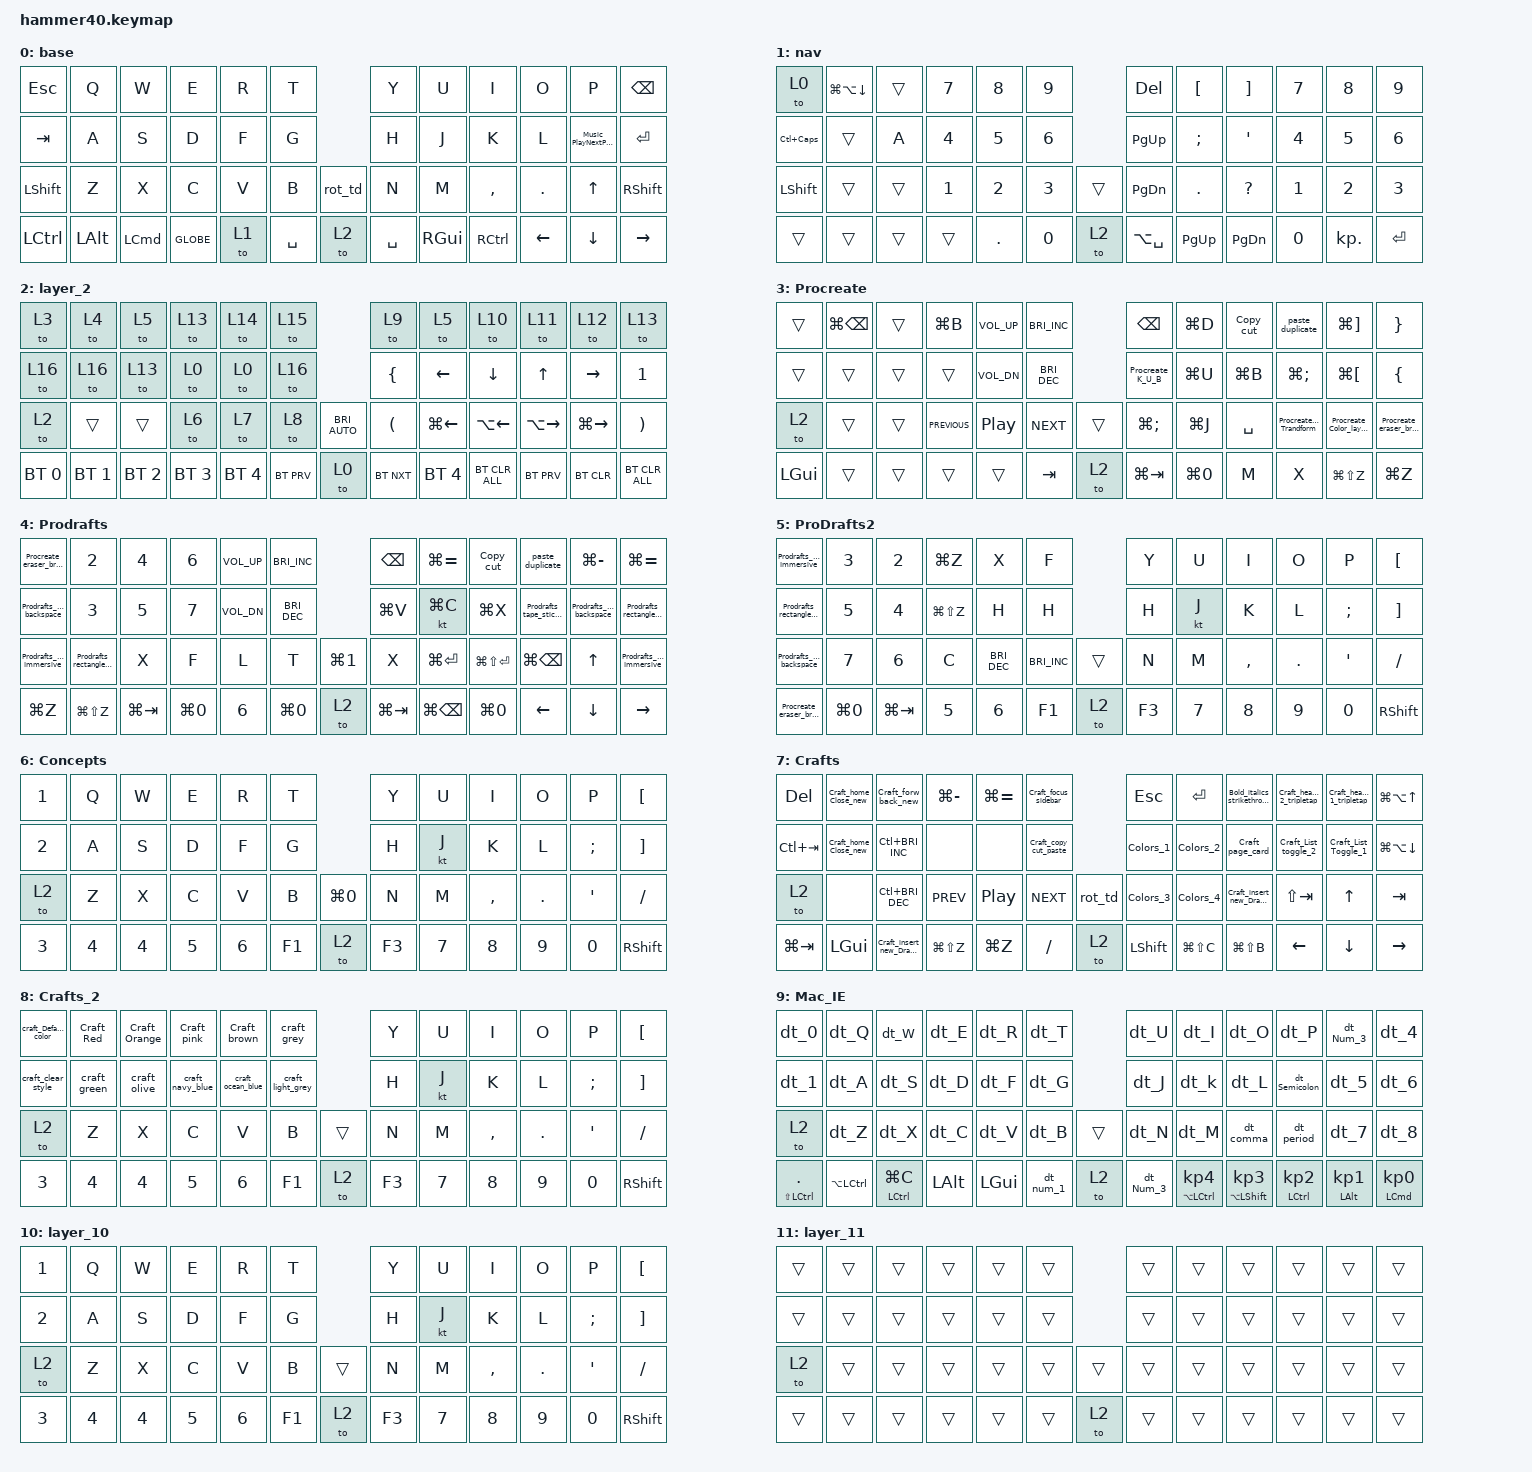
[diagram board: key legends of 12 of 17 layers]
/*
 * Copyright (c) 2020 The ZMK Contributors
 *
 * SPDX-License-Identifier: MIT
 */

#include <behaviors.dtsi>
#include <dt-bindings/zmk/bt.h>
#include <dt-bindings/zmk/keys.h>

/* Layers */

#define BASE 0
#define LOWR 1
#define NAV 2

/ {
    combos {
        compatible = "zmk,combos";

        combo_capsw {
            timeout-ms = <50>;
            key-positions = <16 19>;
            bindings = <&caps_word>;
        };

        combo_bootl {
            timeout-ms = <50>;
            key-positions = <0 1 2>;
            bindings = <&bootloader>;
        };

        combo_reset {
            timeout-ms = <50>;
            key-positions = <10 11 12>;
            bindings = <&sys_reset>;
        };
    };

    behaviors {
        rot_td: rot_tap_dance {
            compatible = "zmk,behavior-tap-dance";
            #binding-cells = <0>;
            tapping-term-ms = <250>;
            bindings = <&kp C_PP>, <&kp C_NEXT>, <&kp C_PREV>;
        };

        ble_encoder: ble_encoder {
            compatible = "zmk,behavior-sensor-rotate";
            #sensor-binding-cells = <0>;
            bindings = <&bt BT_NXT>, <&bt BT_PRV>;
        };

        dt_1: dt_1 {
            compatible = "zmk,behavior-tap-dance";
            label = "DT_1";
            #binding-cells = <0>;
            tapping-term-ms = <250>;
            bindings = <&kp N1>, <&kp RS(NUMBER_1)>, <&kp RA(NUMBER_1)>;
        };

        dt_2: dt_2 {
            compatible = "zmk,behavior-tap-dance";
            label = "DT_2";
            #binding-cells = <0>;
            tapping-term-ms = <250>;
            bindings = <&kp NUMBER_2>, <&kp RS(NUMBER_2)>, <&kp RA(NUMBER_2)>;
        };

        dt_3: dt_3 {
            compatible = "zmk,behavior-tap-dance";
            label = "DT_3";
            #binding-cells = <0>;
            tapping-term-ms = <250>;
            bindings = <&kp NUMBER_3>, <&kp RS(NUMBER_3)>, <&kp RA(NUMBER_3)>;
        };

        dt_0: dt_0 {
            compatible = "zmk,behavior-tap-dance";
            label = "DT_0";
            #binding-cells = <0>;
            tapping-term-ms = <250>;
            bindings = <&kp N0>, <&kp RS(N0)>, <&kp RA(N0)>;
        };

        dt_4: dt_4 {
            compatible = "zmk,behavior-tap-dance";
            label = "DT_4";
            #binding-cells = <0>;
            tapping-term-ms = <250>;
            bindings = <&kp NUMBER_4>, <&kp RS(NUMBER_4)>, <&kp RA(NUMBER_4)>;
        };

        dt_5: dt_5 {
            compatible = "zmk,behavior-tap-dance";
            label = "DT_5";
            #binding-cells = <0>;
            tapping-term-ms = <250>;
            bindings = <&kp N5>, <&kp RS(N5)>, <&kp RA(N5)>;
        };

        dt_6: dt_6 {
            compatible = "zmk,behavior-tap-dance";
            label = "DT_6";
            #binding-cells = <0>;
            tapping-term-ms = <250>;
            bindings = <&kp N6>, <&kp RS(N6)>, <&kp RA(N6)>;
        };

        dt_7: dt_7 {
            compatible = "zmk,behavior-tap-dance";
            label = "DT_7";
            #binding-cells = <0>;
            tapping-term-ms = <250>;
            bindings = <&kp N7>, <&kp RS(N7)>, <&kp RA(N7)>;
        };

        dt_8: dt_8 {
            compatible = "zmk,behavior-tap-dance";
            label = "DT_8";
            #binding-cells = <0>;
            tapping-term-ms = <250>;
            bindings = <&kp N8>, <&kp RS(N8)>, <&kp RA(N8)>;
        };

        dt_9: dt_9 {
            compatible = "zmk,behavior-tap-dance";
            label = "DT_9";
            #binding-cells = <0>;
            tapping-term-ms = <250>;
            bindings = <&kp N9>, <&kp RS(N9)>, <&kp RA(N9)>;
        };

        dt_Q: dt_Q {
            compatible = "zmk,behavior-tap-dance";
            label = "DT_Q";
            #binding-cells = <0>;
            tapping-term-ms = <250>;
            bindings = <&kp Q>, <&kp RS(Q)>, <&kp RA(Q)>;
        };

        dt_W: dt_W {
            compatible = "zmk,behavior-tap-dance";
            label = "DT_W";
            #binding-cells = <0>;
            tapping-term-ms = <250>;
            bindings = <&kp W>, <&kp RS(W)>, <&kp RA(W)>;
        };

        dt_E: dt_E {
            compatible = "zmk,behavior-tap-dance";
            label = "DT_E";
            #binding-cells = <0>;
            tapping-term-ms = <250>;
            bindings = <&kp E>, <&kp RS(E)>, <&kp RA(E)>;
        };

        dt_R: dt_R {
            compatible = "zmk,behavior-tap-dance";
            label = "DT_R";
            #binding-cells = <0>;
            tapping-term-ms = <250>;
            bindings = <&kp R>, <&kp RS(R)>, <&kp RA(R)>;
        };

        dt_T: dt_T {
            compatible = "zmk,behavior-tap-dance";
            label = "DT_T";
            #binding-cells = <0>;
            tapping-term-ms = <250>;
            bindings = <&kp T>, <&kp RS(T)>, <&kp RA(T)>;
        };

        dt_A: dt_A {
            compatible = "zmk,behavior-tap-dance";
            label = "DT_A";
            #binding-cells = <0>;
            tapping-term-ms = <250>;
            bindings = <&kp A>, <&kp RS(A)>, <&kp RA(A)>;
        };

        dt_S: dt_S {
            compatible = "zmk,behavior-tap-dance";
            label = "DT_S";
            #binding-cells = <0>;
            tapping-term-ms = <250>;
            bindings = <&kp S>, <&kp RS(S)>, <&kp RA(S)>;
        };

        dt_D: dt_D {
            compatible = "zmk,behavior-tap-dance";
            label = "DT_D";
            #binding-cells = <0>;
            tapping-term-ms = <250>;
            bindings = <&kp D>, <&kp RS(D)>, <&kp RA(D)>;
        };

        dt_F: dt_F {
            compatible = "zmk,behavior-tap-dance";
            label = "DT_F";
            #binding-cells = <0>;
            tapping-term-ms = <250>;
            bindings = <&kp F>, <&kp RS(F)>, <&kp RA(F)>;
        };

        dt_G: dt_G {
            compatible = "zmk,behavior-tap-dance";
            label = "DT_G";
            #binding-cells = <0>;
            tapping-term-ms = <250>;
            bindings = <&kp G>, <&kp RS(G)>, <&kp RA(G)>;
        };

        dt_Z: dt_Z {
            compatible = "zmk,behavior-tap-dance";
            label = "DT_Z";
            #binding-cells = <0>;
            tapping-term-ms = <250>;
            bindings = <&kp Z>, <&kp RS(Z)>, <&kp RA(Z)>;
        };

        dt_X: dt_X {
            compatible = "zmk,behavior-tap-dance";
            label = "DT_X";
            #binding-cells = <0>;
            tapping-term-ms = <250>;
            bindings = <&kp X>, <&kp RS(X)>, <&kp RA(X)>;
        };

        dt_C: dt_C {
            compatible = "zmk,behavior-tap-dance";
            label = "DT_C";
            #binding-cells = <0>;
            tapping-term-ms = <250>;
            bindings = <&kp C>, <&kp RS(C)>, <&kp RA(C)>;
        };

        dt_V: dt_V {
            compatible = "zmk,behavior-tap-dance";
            label = "DT_V";
            #binding-cells = <0>;
            tapping-term-ms = <250>;
            bindings = <&kp V>, <&kp RS(V)>, <&kp RA(V)>;
        };

        dt_B: dt_B {
            compatible = "zmk,behavior-tap-dance";
            label = "DT_B";
            #binding-cells = <0>;
            tapping-term-ms = <250>;
            bindings = <&kp B>, <&kp RS(B)>, <&kp RA(B)>;
        };

        dt_U: dt_U {
            compatible = "zmk,behavior-tap-dance";
            label = "DT_U";
            #binding-cells = <0>;
            tapping-term-ms = <250>;
            bindings = <&kp U>, <&kp RS(U)>, <&kp RA(U)>;
        };

        dt_I: dt_I {
            compatible = "zmk,behavior-tap-dance";
            label = "DT_I";
            #binding-cells = <0>;
            tapping-term-ms = <250>;
            bindings = <&kp I>, <&kp RS(I)>, <&kp RA(I)>;
        };

        dt_O: dt_O {
            compatible = "zmk,behavior-tap-dance";
            label = "DT_O";
            #binding-cells = <0>;
            tapping-term-ms = <250>;
            bindings = <&kp O>, <&kp RS(O)>, <&kp RA(O)>;
        };

        dt_J: dt_J {
            compatible = "zmk,behavior-tap-dance";
            label = "DT_J";
            #binding-cells = <0>;
            tapping-term-ms = <250>;
            bindings = <&kp J>, <&kp RS(J)>, <&kp RA(J)>;
        };

        dt_k: dt_k {
            compatible = "zmk,behavior-tap-dance";
            label = "DT_K";
            #binding-cells = <0>;
            tapping-term-ms = <250>;
            bindings = <&kp K>, <&kp RS(K)>, <&kp RA(K)>;
        };

        dt_L: dt_L {
            compatible = "zmk,behavior-tap-dance";
            label = "DT_L";
            #binding-cells = <0>;
            tapping-term-ms = <250>;
            bindings = <&kp L>, <&kp RS(L)>, <&kp RA(L)>;
        };

        dt_M: dt_M {
            compatible = "zmk,behavior-tap-dance";
            label = "DT_M";
            #binding-cells = <0>;
            tapping-term-ms = <250>;
            bindings = <&kp M>, <&kp RS(M)>, <&kp RA(M)>;
        };

        dt_N: dt_N {
            compatible = "zmk,behavior-tap-dance";
            label = "DT_N";
            #binding-cells = <0>;
            tapping-term-ms = <250>;
            bindings = <&kp N>, <&kp RS(N)>, <&kp RA(N)>;
        };

        dt_P: dt_P {
            compatible = "zmk,behavior-tap-dance";
            label = "DT_P";
            #binding-cells = <0>;
            tapping-term-ms = <250>;
            bindings = <&kp P>, <&kp RS(P)>, <&kp RA(P)>;
        };

        dt_Semicolon: dt_Semicolon {
            compatible = "zmk,behavior-tap-dance";
            label = "DT_SEMICOLON";
            #binding-cells = <0>;
            tapping-term-ms = <250>;
            bindings = <&kp SEMI>, <&kp RS(SEMI)>, <&kp RA(SEMI)>;
        };

        dt_comma: dt_comma {
            compatible = "zmk,behavior-tap-dance";
            label = "DT_COMMA";
            #binding-cells = <0>;
            tapping-term-ms = <250>;
            bindings = <&kp COMMA>, <&kp RS(COMMA)>, <&kp RA(COMMA)>;
        };

        dt_period: dt_period {
            compatible = "zmk,behavior-tap-dance";
            label = "DT_PERIOD";
            #binding-cells = <0>;
            tapping-term-ms = <250>;
            bindings = <&kp PERIOD>, <&kp RS(PERIOD)>, <&kp RA(PERIOD)>;
        };

        dt_num_1: dt_num_1 {
            compatible = "zmk,behavior-tap-dance";
            label = "DT_NUM_1";
            #binding-cells = <0>;
            tapping-term-ms = <250>;
            bindings =
                <&kp KP_NUMBER_1>,
                <&kp RS(KP_NUMBER_1)>,
                <&kp RA(KP_NUMBER_1)>;
        };

        dt_Num_2: dt_Num_2 {
            compatible = "zmk,behavior-tap-dance";
            label = "DT_NUM_2";
            #binding-cells = <0>;
            tapping-term-ms = <250>;
            bindings =
                <&kp KP_NUMBER_2>,
                <&kp RS(KP_NUMBER_2)>,
                <&kp RA(KP_NUMBER_2)>;
        };

        dt_Num_3: dt_Num_3 {
            compatible = "zmk,behavior-tap-dance";
            label = "DT_NUM_3";
            #binding-cells = <0>;
            tapping-term-ms = <250>;
            bindings =
                <&kp KP_NUMBER_3>,
                <&kp RS(KP_NUMBER_3)>,
                <&kp RA(KP_NUMBER_3)>;
        };

        Prodrafts_100cent_Immersive: Prodrafts_100cent_Immersive {
            compatible = "zmk,behavior-tap-dance";
            label = "PRODRAFTS_100CENT_IMMERSIVE";
            #binding-cells = <0>;
            tapping-term-ms = <250>;
            bindings = <&kp LG(NUMBER_1)>, <&kp LG(LS(F))>;
        };

        Prodrafts_rectangle_Artboard: Prodrafts_rectangle_Artboard {
            compatible = "zmk,behavior-tap-dance";
            label = "PRODRAFTS_RECTANGLE_ARTBOARD";
            #binding-cells = <0>;
            tapping-term-ms = <250>;
            bindings = <&kp R>, <&kp G>;
        };

        Prodrafts_Lasso_backspace: Prodrafts_Lasso_backspace {
            compatible = "zmk,behavior-tap-dance";
            label = "PRODRAFTS_LASSO_BACKSPACE";
            #binding-cells = <0>;
            tapping-term-ms = <250>;
            bindings = <&kp V>, <&kp BACKSPACE>;
        };

        Prodrafts_tape_sticker: Prodrafts_tape_sticker {
            compatible = "zmk,behavior-tap-dance";
            label = "PRODRAFTS_TAPE_STICKER";
            #binding-cells = <0>;
            tapping-term-ms = <250>;
            bindings = <&kp S>, <&kp W>;
        };

        Procreate_eraser_brush: Procreate_eraser_brush {
            compatible = "zmk,behavior-tap-dance";
            label = "PROCREATE_ERASER_BRUSH";
            #binding-cells = <0>;
            tapping-term-ms = <250>;
            bindings = <&kp NUMBER_1>, <&kp E>;
        };

        Procreate_Color_layers: Procreate_Color_layers {
            compatible = "zmk,behavior-tap-dance";
            label = "PROCREATE_COLOR_LAYERS";
            #binding-cells = <0>;
            tapping-term-ms = <250>;
            bindings = <&kp C>, <&kp L>;
        };

        Procreate_selection_Trandform: Procreate_selection_Trandform {
            compatible = "zmk,behavior-tap-dance";
            label = "PROCREATE_SELECTION_TRANDFORM";
            #binding-cells = <0>;
            tapping-term-ms = <250>;
            bindings = <&kp S>, <&kp V>;
        };

        Copy_cut: Copy_cut {
            compatible = "zmk,behavior-tap-dance";
            label = "COPY_CUT";
            #binding-cells = <0>;
            tapping-term-ms = <250>;
            bindings = <&kp LG(C)>, <&kp LG(X)>;
        };

        paste_duplicate: paste_duplicate {
            compatible = "zmk,behavior-tap-dance";
            label = "PASTE_DUPLICATE";
            #binding-cells = <0>;
            tapping-term-ms = <250>;
            bindings = <&kp LG(V)>, <&kp LG(J)>;
        };

        Procreate_K_U_B: Procreate_K_U_B {
            compatible = "zmk,behavior-tap-dance";
            label = "PROCREATE_K_U_B";
            #binding-cells = <0>;
            tapping-term-ms = <250>;
            bindings = <&kp LG(K)>, <&kp LG(U)>, <&kp LG(B)>;
        };

        new_behavior: new_behavior {
            compatible = "zmk,behavior-tap-dance";
            label = "NEW_BEHAVIOR";
            #binding-cells = <0>;
            tapping-term-ms = <250>;
            bindings = <&kp C>, <&kp L>;
        };

        Notability_Tool_1: Notability_Tool_1 {
            compatible = "zmk,behavior-tap-dance";
            label = "NOTABILITY_TOOL_1";
            #binding-cells = <0>;
            tapping-term-ms = <250>;
            bindings =
                <&kp LG(NUMBER_1)>,
                <&kp LG(NUMBER_2)>,
                <&kp LG(NUMBER_3)>;
        };

        Notability_tool_2: Notability_tool_2 {
            compatible = "zmk,behavior-tap-dance";
            label = "NOTABILITY_TOOL_2";
            #binding-cells = <0>;
            tapping-term-ms = <250>;
            bindings = <&kp LG(NUMBER_4)>, <&kp LG(N5)>, <&kp LG(NUMBER_6)>;
        };

        Notability_color_2: Notability_color_2 {
            compatible = "zmk,behavior-tap-dance";
            label = "NOTABILITY_COLOR_2";
            #binding-cells = <0>;
            tapping-term-ms = <250>;
            bindings =
                <&kp LG(LA(NUMBER_4))>,
                <&kp LG(LA(N5))>,
                <&kp LG(LA(NUMBER_6))>;
        };

        Notabiltiy_color_1: Notabiltiy_color_1 {
            compatible = "zmk,behavior-tap-dance";
            label = "NOTABILTIY_COLOR_1";
            #binding-cells = <0>;
            tapping-term-ms = <250>;
            bindings =
                <&kp LG(LA(NUMBER_1))>,
                <&kp LG(LA(NUMBER_2))>,
                <&kp LG(LA(NUMBER_3))>;
        };

        AppleBooks_Theme_1: AppleBooks_Theme_1 {
            compatible = "zmk,behavior-tap-dance";
            label = "APPLEBOOKS_THEME_1";
            #binding-cells = <0>;
            tapping-term-ms = <250>;
            bindings =
                <&kp LG(LC(NUMBER_1))>,
                <&kp LG(LC(NUMBER_2))>,
                <&kp LG(LC(NUMBER_3))>;
        };

        AppleBooks_theme_2: AppleBooks_theme_2 {
            compatible = "zmk,behavior-tap-dance";
            label = "APPLEBOOKS_THEME_2";
            #binding-cells = <0>;
            tapping-term-ms = <250>;
            bindings =
                <&kp LG(LC(NUMBER_4))>,
                <&kp LG(LC(N5))>,
                <&kp LG(LC(NUMBER_6))>;
        };

        AppleBooks_bookmarks_notes: AppleBooks_bookmarks_notes {
            compatible = "zmk,behavior-tap-dance";
            label = "APPLEBOOKS_BOOKMARKS_NOTES";
            #binding-cells = <0>;
            tapping-term-ms = <250>;
            bindings = <&kp LG(LS(D))>, <&kp LG(LS(N))>;
        };

        AppleBooks_light_dark: AppleBooks_light_dark {
            compatible = "zmk,behavior-tap-dance";
            label = "APPLEBOOKS_LIGHT_DARK";
            #binding-cells = <0>;
            tapping-term-ms = <250>;
            bindings = <&kp LG(LS(LA(NUMBER_1)))>, <&kp LG(LS(LA(NUMBER_2)))>;
        };

        Notability_size: Notability_size {
            compatible = "zmk,behavior-tap-dance";
            label = "NOTABILITY_SIZE";
            #binding-cells = <0>;
            tapping-term-ms = <250>;
            bindings =
                <&kp LA(LC(NUMBER_1))>,
                <&kp LA(LC(NUMBER_2))>,
                <&kp LA(LC(NUMBER_3))>;
        };

        Notability_color_swtch: Notability_color_swtch {
            compatible = "zmk,behavior-tap-dance";
            label = "NOTABILITY_COLOR_SWTCH";
            #binding-cells = <0>;
            tapping-term-ms = <250>;
            bindings = <&kp LA(LG(N0))>, <&kp LA(LG(N9))>;
        };

        Noteful_pen_highlight: Noteful_pen_highlight {
            compatible = "zmk,behavior-tap-dance";
            label = "NOTEFUL_PEN_HIGHLIGHT";
            #binding-cells = <0>;
            tapping-term-ms = <250>;
            bindings = <&kp F>, <&kp G>;
        };

        Noteful_Lasso_eraser: Noteful_Lasso_eraser {
            compatible = "zmk,behavior-tap-dance";
            label = "NOTEFUL_LASSO_ERASER";
            #binding-cells = <0>;
            tapping-term-ms = <250>;
            bindings = <&kp A>, <&kp E>;
        };

        Noteful_color_1: Noteful_color_1 {
            compatible = "zmk,behavior-tap-dance";
            label = "NOTEFUL_COLOR_1";
            #binding-cells = <0>;
            tapping-term-ms = <250>;
            bindings = <&kp NUMBER_1>, <&kp NUMBER_2>, <&kp NUMBER_3>;
        };

        Noteful_color_2: Noteful_color_2 {
            compatible = "zmk,behavior-tap-dance";
            label = "NOTEFUL_COLOR_2";
            #binding-cells = <0>;
            tapping-term-ms = <250>;
            bindings = <&kp NUMBER_4>, <&kp N5>, <&kp NUMBER_6>;
        };

        Noteful_zoom_fit_100: Noteful_zoom_fit_100 {
            compatible = "zmk,behavior-tap-dance";
            label = "NOTEFUL_ZOOM_FIT_100";
            #binding-cells = <0>;
            tapping-term-ms = <250>;
            bindings = <&kp LG(N0)>, <&kp LG(LA(N0))>;
        };

        Craft_headings_1_tripletap: Craft_headings_1_tripletap {
            compatible = "zmk,behavior-tap-dance";
            label = "CRAFT_HEADINGS_1_TRIPLETAP";
            #binding-cells = <0>;
            tapping-term-ms = <250>;
            bindings =
                <&kp LC(NUMBER_1)>,
                <&kp LC(NUMBER_2)>,
                <&kp LC(NUMBER_3)>;
        };

        Craft_headings_2_tripletap: Craft_headings_2_tripletap {
            compatible = "zmk,behavior-tap-dance";
            label = "CRAFT_HEADINGS_2_TRIPLETAP";
            #binding-cells = <0>;
            tapping-term-ms = <250>;
            bindings = <&kp LC(NUMBER_4)>, <&kp LC(N5)>, <&kp LC(NUMBER_6)>;
        };

        Craft_List_Toggle_1: Craft_List_Toggle_1 {
            compatible = "zmk,behavior-tap-dance";
            label = "CRAFT_LIST_TOGGLE_1";
            #binding-cells = <0>;
            tapping-term-ms = <250>;
            bindings = <&kp LG(LA(N7))>, <&kp LA(LG(N8))>, <&kp LA(LG(N9))>;
        };

        Craft_List_toggle_2: Craft_List_toggle_2 {
            compatible = "zmk,behavior-tap-dance";
            label = "CRAFT_LIST_TOGGLE_2";
            #binding-cells = <0>;
            tapping-term-ms = <250>;
            bindings = <&kp LG(LA(NUMBER_6))>, <&kp LA(LG(T))>;
        };

        Colors_1: Colors_1 {
            compatible = "zmk,behavior-tap-dance";
            label = "COLORS_1";
            #binding-cells = <0>;
            tapping-term-ms = <250>;
            bindings = <&craft_Default_color>, <&Craft_Red>, <&Craft_Orange>;
        };

        Colors_2: Colors_2 {
            compatible = "zmk,behavior-tap-dance";
            label = "COLORS_2";
            #binding-cells = <0>;
            tapping-term-ms = <250>;
            bindings = <&Craft_Red>, <&Craft_Orange>, <&Craft_pink>;
        };

        Colors_3: Colors_3 {
            compatible = "zmk,behavior-tap-dance";
            label = "COLORS_3";
            #binding-cells = <0>;
            tapping-term-ms = <250>;
            bindings = <&craft_green>, <&craft_olive>, <&Craft_Orange>;
        };

        Colors_4: Colors_4 {
            compatible = "zmk,behavior-tap-dance";
            label = "COLORS_4";
            #binding-cells = <0>;
            tapping-term-ms = <250>;
            bindings = <&craft_navy_blue>, <&craft_ocean_blue>, <&Craft_brown>;
        };

        Craft_clean_format_color: Craft_clean_format_color {
            compatible = "zmk,behavior-tap-dance";
            label = "CRAFT_CLEAN_FORMAT_COLOR";
            #binding-cells = <0>;
            tapping-term-ms = <250>;
            bindings = <&kp LG(LA(NUMBER_0))>, <&craft_clear_style>;
        };

        Craft_focus_sidebar: Craft_focus_sidebar {
            compatible = "zmk,behavior-tap-dance";
            label = "CRAFT_FOCUS_SIDEBAR";
            #binding-cells = <0>;
            tapping-term-ms = <250>;
            bindings = <&kp LC(PERIOD)>, <&kp LG(BACKSLASH)>;
        };

        Craft_forw_back_new: Craft_forw_back_new {
            compatible = "zmk,behavior-tap-dance";
            label = "CRAFT_FORW_BACK_NEW";
            #binding-cells = <0>;
            tapping-term-ms = <250>;
            bindings = <&kp LG(LEFT_BRACKET)>, <&kp LG(RIGHT_BRACKET)>;
        };

        Craft_page_card: Craft_page_card {
            compatible = "zmk,behavior-tap-dance";
            label = "CRAFT_PAGE_CARD";
            #binding-cells = <0>;
            tapping-term-ms = <250>;
            bindings = <&kp LG(LS(P))>, <&kp LG(LS(L))>, <&kp LG(LS(APOS))>;
        };

        Bold_italics_strikethrough: Bold_italics_strikethrough {
            compatible = "zmk,behavior-tap-dance";
            label = "BOLD_ITALICS_STRIKETHROUGH";
            #binding-cells = <0>;
            tapping-term-ms = <250>;
            bindings = <&kp LG(B)>, <&kp LG(I)>, <&kp LG(LS(MINUS))>;
        };

        Craft_Group_ungroup: Craft_Group_ungroup {
            compatible = "zmk,behavior-tap-dance";
            label = "CRAFT_GROUP_UNGROUP";
            #binding-cells = <0>;
            tapping-term-ms = <250>;
            bindings = <&kp LG(G)>, <&kp LG(LS(G))>;
        };

        Craft_copy_cut_paste: Craft_copy_cut_paste {
            compatible = "zmk,behavior-tap-dance";
            label = "CRAFT_COPY_CUT_PASTE";
            #binding-cells = <0>;
            tapping-term-ms = <250>;
            bindings = <&kp LG(C)>, <&kp LG(V)>, <&kp LG(X)>;
        };

        Craft_home_Close_new: Craft_home_Close_new {
            compatible = "zmk,behavior-tap-dance";
            label = "CRAFT_HOME_CLOSE_NEW";
            #binding-cells = <0>;
            tapping-term-ms = <250>;
            bindings = <&kp LG(T)>, <&kp LG(W)>, <&kp LG(N)>;
        };

        MN_View_Vertical_Horizontal: MN_View_Vertical_Horizontal {
            compatible = "zmk,behavior-tap-dance";
            label = "MN_VIEW_VERTICAL_HORIZONTAL";
            #binding-cells = <0>;
            tapping-term-ms = <250>;
            bindings = <&kp LA(O)>, <&kp LA(P)>;
        };

        MN_TOC_Thumbnails: MN_TOC_Thumbnails {
            compatible = "zmk,behavior-tap-dance";
            label = "MN_TOC_THUMBNAILS";
            #binding-cells = <0>;
            tapping-term-ms = <250>;
            bindings = <&kp LG(D)>, <&kp LG(LS(G))>;
        };

        Music_PlayNextPrevious: Music_PlayNextPrevious {
            compatible = "zmk,behavior-tap-dance";
            label = "MUSIC_PLAYNEXTPREVIOUS";
            #binding-cells = <0>;
            bindings = <&kp C_PLAY_PAUSE>, <&kp C_NEXT>, <&kp C_PREV>;
        };
    };

    macros {
        Craft_insert_new_Drawing: Craft_insert_new_Drawing {
            compatible = "zmk,behavior-macro";
            #binding-cells = <0>;
            bindings = <&kp FSLH &kp I &kp N &kp S &kp E &kp R &kp T &kp SPACE &kp N &kp E &kp W &kp SPACE &kp D &kp R &kp A &kp W &kp I &kp N &kp G &kp RET>;
            label = "CRAFT_INSERT_NEW_DRAWING";
        };

        Craft_Red: Craft_Red {
            compatible = "zmk,behavior-macro";
            #binding-cells = <0>;
            bindings = <&kp FSLH &kp R &kp E &kp D &kp RET>;
            label = "CRAFT_RED";
        };

        Craft_Orange: Craft_Orange {
            compatible = "zmk,behavior-macro";
            #binding-cells = <0>;
            bindings = <&kp FSLH &kp O &kp R &kp A &kp N &kp G &kp E &kp RET>;
            label = "CRAFT_ORANGE";
        };

        Craft_pink: Craft_pink {
            compatible = "zmk,behavior-macro";
            #binding-cells = <0>;
            bindings = <&kp FSLH &kp P &kp I &kp N &kp K &kp RET>;
            label = "CRAFT_PINK";
        };

        Craft_brown: Craft_brown {
            compatible = "zmk,behavior-macro";
            #binding-cells = <0>;
            bindings = <&kp FSLH &kp B &kp R &kp O &kp W &kp N &kp RET>;
            label = "CRAFT_BROWN";
        };

        Craft_Purple: Craft_Purple {
            compatible = "zmk,behavior-macro";
            #binding-cells = <0>;
            bindings = <&kp FSLH &kp P &kp U &kp R &kp P &kp L &kp E &kp RET>;
            label = "CRAFT_PURPLE";
        };

        craft_olive: craft_olive {
            compatible = "zmk,behavior-macro";
            #binding-cells = <0>;
            bindings = <&kp FSLH &kp O &kp L &kp I &kp V &kp E &kp RET>;
            label = "CRAFT_OLIVE";
        };

        craft_Default_color: craft_Default_color {
            compatible = "zmk,behavior-macro";
            #binding-cells = <0>;
            bindings = <&kp FSLH &kp D &kp E &kp F &kp A &kp U &kp L &kp T &kp SPACE &kp C &kp O &kp L &kp O &kp R &kp RET>;
            label = "CRAFT_DEFAULT_COLOR";
        };

        craft_grey: craft_grey {
            compatible = "zmk,behavior-macro";
            #binding-cells = <0>;
            bindings = <&kp FSLH &kp G &kp R &kp E &kp Y &kp RET>;
            label = "CRAFT_GREY";
        };

        craft_light_grey: craft_light_grey {
            compatible = "zmk,behavior-macro";
            #binding-cells = <0>;
            bindings = <&kp FSLH &kp L &kp I &kp G &kp H &kp T &kp SPACE &kp G &kp R &kp E &kp Y &kp RET>;
            label = "CRAFT_LIGHT_GREY";
        };

        craft_navy_blue: craft_navy_blue {
            compatible = "zmk,behavior-macro";
            #binding-cells = <0>;
            bindings = <&kp FSLH &kp N &kp A &kp V &kp Y &kp SPACE &kp B &kp L &kp U &kp E &kp RET>;
            label = "CRAFT_NAVY_BLUE";
        };

        craft_ocean_blue: craft_ocean_blue {
            compatible = "zmk,behavior-macro";
            #binding-cells = <0>;
            bindings = <&kp FSLH &kp O &kp C &kp E &kp A &kp N &kp SPACE &kp B &kp L &kp U &kp E &kp RET>;
            label = "CRAFT_OCEAN_BLUE";
        };

        craft_green: craft_green {
            compatible = "zmk,behavior-macro";
            #binding-cells = <0>;
            bindings = <&kp FSLH &kp G &kp R &kp E &kp E &kp N &kp RET>;
            label = "CRAFT_GREEN";
        };

        craft_table: craft_table {
            compatible = "zmk,behavior-macro";
            #binding-cells = <0>;
            bindings = <&kp FSLH &kp T &kp A &kp B &kp L &kp E>;
            label = "CRAFT_TABLE";
        };

        craft_clear_style: craft_clear_style {
            compatible = "zmk,behavior-macro";
            #binding-cells = <0>;
            bindings = <&kp FSLH &kp C &kp L &kp E &kp A &kp R &kp SPACE &kp S &kp T &kp Y &kp L &kp I &kp N &kp G &kp RET>;
            label = "CRAFT_CLEAR_STYLE";
        };

        Craft_page_break: Craft_page_break {
            compatible = "zmk,behavior-macro";
            #binding-cells = <0>;
            bindings = <&kp FSLH &kp P &kp A &kp G &kp E &kp SPACE &kp B &kp R &kp E &kp A &kp K>;
            label = "CRAFT_PAGE_BREAK";
        };

        Craft_move_to: Craft_move_to {
            compatible = "zmk,behavior-macro";
            #binding-cells = <0>;
            bindings = <&kp FSLH &kp M &kp O &kp V &kp E &kp SPACE &kp T &kp O &kp RET>;
            label = "CRAFT_MOVE_TO";
        };

        craft_image: craft_image {
            compatible = "zmk,behavior-macro";
            #binding-cells = <0>;
            bindings = <&kp FSLH &kp I &kp M &kp A &kp G &kp E>;
            label = "CRAFT_IMAGE";
        };

        Ipad_prodrafts: Ipad_prodrafts {
            compatible = "zmk,behavior-macro";
            #binding-cells = <0>;
            bindings = <&bt BT_SEL 1>, <&macro_wait_time 400>, <&to 4>;

            label = "IPAD_PRODRAFTS";
        };

        Mac_indian_express: Mac_indian_express {
            compatible = "zmk,behavior-macro";
            #binding-cells = <0>;
            bindings = <&bt BT_SEL 0>, <&macro_wait_time 400>, <&to 9>;

            label = "MAC_INDIAN_EXPRESS";
        };
    };

    keymap {
        compatible = "zmk,keymap";

        default_layer {
            display-name = "base";
            sensor-bindings = <&inc_dec_kp C_VOL_UP C_VOL_DN>;
            bindings = <
&kp ESCAPE  &kp Q     &kp W     &kp E      &kp R  &kp T               &kp Y      &kp U     &kp I      &kp O       &kp P                    &kp BACKSPACE
&kp TAB     &kp A     &kp S     &kp D      &kp F  &kp G               &kp H      &kp J     &kp K      &kp L       &Music_PlayNextPrevious  &kp ENTER
&kp LSHFT   &kp Z     &kp X     &kp C      &kp V  &kp B      &rot_td  &kp N      &kp M     &kp COMMA  &kp PERIOD  &kp UP_ARROW             &kp RSHFT
&kp LCTRL   &kp LALT  &kp LCMD  &kp GLOBE  &to 1  &kp SPACE  &to 2    &kp SPACE  &kp RGUI  &kp RCTRL  &kp LEFT    &kp DOWN_ARROW           &kp RIGHT
            >;
        };

        nav_layer {
            display-name = "nav";
            bindings = <
&to 0             &kp LG(LA(DOWN))  &trans  &kp N7        &kp N8        &kp N9                &kp DELETE     &kp LEFT_BRACKET  &kp RIGHT_BRACKET  &kp N7        &kp N8        &kp N9
&kp LC(CAPSLOCK)  &trans            &kp A   &kp NUMBER_4  &kp N5        &kp NUMBER_6          &kp PAGE_UP    &kp SEMI          &kp APOSTROPHE     &kp NUMBER_4  &kp N5        &kp NUMBER_6
&kp LEFT_SHIFT    &trans            &trans  &kp NUMBER_1  &kp NUMBER_2  &kp NUMBER_3  &trans  &kp PAGE_DOWN  &kp PERIOD        &kp QUESTION       &kp NUMBER_1  &kp NUMBER_2  &kp NUMBER_3
&trans            &trans            &trans  &trans        &kp DOT       &kp N0        &to 2   &kp LA(SPACE)  &kp PAGE_UP       &kp PAGE_DOWN      &kp N0        &kp KP_DOT    &kp ENTER
            >;

            sensor-bindings = <&inc_dec_kp C_BRIGHTNESS_INC C_BRIGHTNESS_DEC>;
        };

        layer_2 {
            bindings = <
&to 3         &to 4         &to 5         &to 13        &to 14        &to 15                             &to 9                 &to 5         &to 10              &to 11         &to 12         &to 13
&to 16        &to 16        &to 13        &to 0         &to 0         &to 16                             &kp LEFT_BRACE        &kp LEFT      &kp DOWN            &kp UP         &kp RIGHT      &kp NUMBER_1
&to 2         &trans        &trans        &to 6         &to 7         &to 8       &kp C_BRIGHTNESS_AUTO  &kp LEFT_PARENTHESIS  &kp LG(LEFT)  &kp LA(LEFT_ARROW)  &kp LA(RIGHT)  &kp LG(RIGHT)  &kp RIGHT_PARENTHESIS
&bt BT_SEL 0  &bt BT_SEL 1  &bt BT_SEL 2  &bt BT_SEL 3  &bt BT_SEL 4  &bt BT_PRV  &to 0                  &bt BT_NXT            &bt BT_SEL 4  &bt BT_CLR_ALL      &bt BT_PRV     &bt BT_CLR     &bt BT_CLR_ALL
            >;

            sensor-bindings = <&inc_dec_kp C_BRIGHTNESS_INC C_BRIGHTNESS_DEC>;
        };

        Procreate {
            bindings = <
&trans        &kp LG(BACKSPACE)  &trans  &kp LG(B)       &kp C_VOLUME_UP   &kp C_BRIGHTNESS_INC          &kp BACKSPACE      &kp LG(D)   &Copy_cut  &paste_duplicate                &kp LG(RIGHT_BRACKET)    &kp RIGHT_BRACE
&trans        &trans             &trans  &trans          &kp C_VOL_DN      &kp C_BRIGHTNESS_DEC          &Procreate_K_U_B   &kp LG(U)   &kp LG(B)  &kp LG(SEMI)                    &kp LG(LEFT_BRACKET)     &kp LEFT_BRACE
&to 2         &trans             &trans  &kp C_PREVIOUS  &kp C_PLAY_PAUSE  &kp C_NEXT            &trans  &kp LG(SEMICOLON)  &kp LG(J)   &kp SPACE  &Procreate_selection_Trandform  &Procreate_Color_layers  &Procreate_eraser_brush
&kp LEFT_GUI  &trans             &trans  &trans          &trans            &kp TAB               &to 2   &kp LG(TAB)        &kp LG(N0)  &kp M      &kp X                           &kp LG(LS(Z))            &kp LG(Z)
            >;

            sensor-bindings = <&inc_dec_kp LG(LEFT_BRACKET) LG(RIGHT_BRACKET)>;
        };

        Prodrafts {
            bindings = <
&Procreate_eraser_brush       &kp NUMBER_2                   &kp NUMBER_4  &kp NUMBER_6  &kp C_VOLUME_UP  &kp C_BRIGHTNESS_INC                    &kp BACKSPACE  &kp LG(EQUAL)      &Copy_cut          &paste_duplicate         &kp LG(MINUS)               &kp LG(EQUAL)
&Prodrafts_Lasso_backspace    &kp NUMBER_3                   &kp N5        &kp N7        &kp C_VOL_DN     &kp C_BRIGHTNESS_DEC                    &kp LG(V)      &kt LG(C)          &kp LG(X)          &Prodrafts_tape_sticker  &Prodrafts_Lasso_backspace  &Prodrafts_rectangle_Artboard
&Prodrafts_100cent_Immersive  &Prodrafts_rectangle_Artboard  &kp X         &kp F         &kp L            &kp T                 &kp LG(NUMBER_1)  &kp X          &kp LG(ENTER)      &kp LG(LS(ENTER))  &kp LG(BACKSPACE)        &kp UP_ARROW                &Prodrafts_100cent_Immersive
&kp LG(Z)                     &kp LG(LS(Z))                  &kp LG(TAB)   &kp LG(N0)    &kp NUMBER_6     &kp LG(N0)            &to 2             &kp LG(TAB)    &kp LG(BACKSPACE)  &kp LG(N0)         &kp LEFT                 &kp DOWN_ARROW              &kp RIGHT
            >;

            sensor-bindings = <&inc_dec_kp LG(PLUS) LG(MINUS)>;
        };

        ProDrafts2 {
            bindings = <
&Prodrafts_100cent_Immersive   &kp NUMBER_3  &kp NUMBER_2  &kp LG(Z)      &kp X                 &kp F                         &kp Y   &kp U   &kp I      &kp O       &kp P          &kp LEFT_BRACKET
&Prodrafts_rectangle_Artboard  &kp N5        &kp NUMBER_4  &kp LG(LS(Z))  &kp H                 &kp H                         &kp H   &kt J   &kp K      &kp L       &kp SEMICOLON  &kp RIGHT_BRACKET
&Prodrafts_Lasso_backspace     &kp N7        &kp NUMBER_6  &kp C          &kp C_BRIGHTNESS_DEC  &kp C_BRIGHTNESS_INC  &trans  &kp N   &kp M   &kp COMMA  &kp PERIOD  &kp APOS       &kp SLASH
&Procreate_eraser_brush        &kp LG(N0)    &kp LG(TAB)   &kp N5         &kp NUMBER_6          &kp F1                &to 2   &kp F3  &kp N7  &kp N8     &kp N9      &kp N0         &kp RIGHT_SHIFT
            >;

            sensor-bindings = <&inc_dec_kp LG(PLUS) LG(MINUS)>;
        };

        Concepts {
            bindings = <
&kp NUMBER_1  &kp Q         &kp W         &kp E   &kp R         &kp T               &kp Y   &kp U   &kp I      &kp O       &kp P          &kp LEFT_BRACKET
&kp NUMBER_2  &kp A         &kp S         &kp D   &kp F         &kp G               &kp H   &kt J   &kp K      &kp L       &kp SEMICOLON  &kp RIGHT_BRACKET
&to 2         &kp Z         &kp X         &kp C   &kp V         &kp B   &kp LG(N0)  &kp N   &kp M   &kp COMMA  &kp PERIOD  &kp APOS       &kp SLASH
&kp NUMBER_3  &kp NUMBER_4  &kp NUMBER_4  &kp N5  &kp NUMBER_6  &kp F1  &to 2       &kp F3  &kp N7  &kp N8     &kp N9      &kp N0         &kp RIGHT_SHIFT
            >;

            sensor-bindings = <&inc_dec_kp LG(PLUS) LG(MINUS)>;
        };

        Crafts {
            bindings = <
&kp DELETE   &Craft_home_Close_new  &Craft_forw_back_new       &kp LG(MINUS)  &kp LG(EQUAL)  &Craft_focus_sidebar            &kp ESCAPE      &kp ENTER      &Bold_italics_strikethrough  &Craft_headings_2_tripletap  &Craft_headings_1_tripletap  &kp LG(LA(UP_ARROW))
&kp LC(TAB)  &Craft_home_Close_new  &kp LC(C_BRIGHTNESS_INC)   &none          &none          &Craft_copy_cut_paste           &Colors_1       &Colors_2      &Craft_page_card             &Craft_List_toggle_2         &Craft_List_Toggle_1         &kp LG(LA(DOWN_ARROW))
&to 2        &none                  &kp LC(C_BRIGHTNESS_DEC)   &kp C_PREV     &kp C_PP       &kp C_NEXT             &rot_td  &Colors_3       &Colors_4      &Craft_insert_new_Drawing    &kp LS(TAB)                  &kp UP_ARROW                 &kp TAB
&kp LG(TAB)  &kp LEFT_GUI           &Craft_insert_new_Drawing  &kp LG(LS(Z))  &kp LG(Z)      &kp SLASH              &to 2    &kp LEFT_SHIFT  &kp LG(LS(C))  &kp LG(LS(B))                &kp LEFT                     &kp DOWN_ARROW               &kp RIGHT
            >;

            sensor-bindings = <&inc_dec_kp C_VOLUME_UP C_VOL_DN>;
        };

        Crafts_2 {
            bindings = <
&craft_Default_color  &Craft_Red    &Craft_Orange  &Craft_pink       &Craft_brown       &craft_grey                &kp Y   &kp U   &kp I      &kp O       &kp P          &kp LEFT_BRACKET
&craft_clear_style    &craft_green  &craft_olive   &craft_navy_blue  &craft_ocean_blue  &craft_light_grey          &kp H   &kt J   &kp K      &kp L       &kp SEMICOLON  &kp RIGHT_BRACKET
&to 2                 &kp Z         &kp X          &kp C             &kp V              &kp B              &trans  &kp N   &kp M   &kp COMMA  &kp PERIOD  &kp APOS       &kp SLASH
&kp NUMBER_3          &kp NUMBER_4  &kp NUMBER_4   &kp N5            &kp NUMBER_6       &kp F1             &to 2   &kp F3  &kp N7  &kp N8     &kp N9      &kp N0         &kp RIGHT_SHIFT
            >;

            sensor-bindings = <&inc_dec_kp LC(EQUAL) LC(MINUS)>;
        };

        Mac_IE {
            bindings = <
&dt_0                        &dt_Q                 &dt_W                   &dt_E         &dt_R         &dt_T              &dt_U      &dt_I                             &dt_O                           &dt_P                         &dt_Num_3                 &dt_4
&dt_1                        &dt_A                 &dt_S                   &dt_D         &dt_F         &dt_G              &dt_J      &dt_k                             &dt_L                           &dt_Semicolon                 &dt_5                     &dt_6
&to 2                        &dt_Z                 &dt_X                   &dt_C         &dt_V         &dt_B      &trans  &dt_N      &dt_M                             &dt_comma                       &dt_period                    &dt_7                     &dt_8
&mt LS(LEFT_CONTROL) PERIOD  &kp LA(LEFT_CONTROL)  &mt LEFT_CONTROL LG(C)  &kp LEFT_ALT  &kp LEFT_GUI  &dt_num_1  &to 2   &dt_Num_3  &mt LA(LEFT_CONTROL) KP_NUMBER_4  &mt LA(LEFT_SHIFT) KP_NUMBER_3  &mt LEFT_CONTROL KP_NUMBER_2  &mt LEFT_ALT KP_NUMBER_1  &mt LEFT_COMMAND KP_N0
            >;

            sensor-bindings = <&inc_dec_kp LG(PLUS) LG(MINUS)>;
        };

        layer_10 {
            bindings = <
&kp NUMBER_1  &kp Q         &kp W         &kp E   &kp R         &kp T           &kp Y   &kp U   &kp I      &kp O       &kp P          &kp LEFT_BRACKET
&kp NUMBER_2  &kp A         &kp S         &kp D   &kp F         &kp G           &kp H   &kt J   &kp K      &kp L       &kp SEMICOLON  &kp RIGHT_BRACKET
&to 2         &kp Z         &kp X         &kp C   &kp V         &kp B   &trans  &kp N   &kp M   &kp COMMA  &kp PERIOD  &kp APOS       &kp SLASH
&kp NUMBER_3  &kp NUMBER_4  &kp NUMBER_4  &kp N5  &kp NUMBER_6  &kp F1  &to 2   &kp F3  &kp N7  &kp N8     &kp N9      &kp N0         &kp RIGHT_SHIFT
            >;

            sensor-bindings = <&inc_dec_kp LG(PLUS) LG(MINUS)>;
        };

        layer_11 {
            bindings = <
&trans  &trans  &trans  &trans  &trans  &trans          &trans  &trans  &trans  &trans  &trans  &trans
&trans  &trans  &trans  &trans  &trans  &trans          &trans  &trans  &trans  &trans  &trans  &trans
&to 2   &trans  &trans  &trans  &trans  &trans  &trans  &trans  &trans  &trans  &trans  &trans  &trans
&trans  &trans  &trans  &trans  &trans  &trans  &to 2   &trans  &trans  &trans  &trans  &trans  &trans
            >;
        };

        layer_12 {
            bindings = <
&trans  &trans  &trans  &trans  &trans  &trans          &trans  &trans  &trans  &trans  &trans  &trans
&trans  &trans  &trans  &trans  &trans  &trans          &trans  &trans  &trans  &trans  &trans  &trans
&to 2   &trans  &trans  &trans  &trans  &trans  &trans  &trans  &trans  &trans  &trans  &trans  &trans
&trans  &trans  &trans  &trans  &trans  &trans  &to 2   &trans  &trans  &trans  &trans  &trans  &trans
            >;
        };

        Apple_books {
            bindings = <
&kp LEFT_ARROW       &kp RIGHT                    &kp LG(T)               &kp LG(LEFT_BRACKET)  &kp C_VOLUME_UP  &kp C_BRIGHTNESS_INC              &kp BACKSPACE  &trans  &trans  &trans                  &kp LA(LEFT_ARROW)           &kp LA(RIGHT)
&AppleBooks_Theme_1  &AppleBooks_theme_2          &AppleBooks_light_dark  &kp LG(LC(COMMA))     &kp C_VOL_DN     &kp C_BRIGHTNESS_DEC              &trans         &trans  &trans  &kp LG(LC(COMMA))       &AppleBooks_theme_2          &AppleBooks_Theme_1
&kp LG(T)            &AppleBooks_bookmarks_notes  &kp LG(D)               &kp LG(N0)            &kp LG(MINUS)    &kp LG(PLUS)          &kp LG(N0)  &trans         &trans  &trans  &AppleBooks_light_dark  &AppleBooks_bookmarks_notes  &kp LG(T)
&kp LEFT_ARROW       &kp RIGHT                    &kp LG(Z)               &kp LA(LEFT)          &kp LA(RIGHT)    &kp LG(TAB)           &to 2       &trans         &trans  &trans  &kp LG(Z)               &kp LEFT                     &kp RIGHT
            >;

            sensor-bindings = <&inc_dec_kp LG(EQUAL) LG(MINUS)>;
        };

        Noteful {
            bindings = <
&kp F        &kp E          &kp H             &kp LG(LA(N0))  &kp RBRC          &kp C_BRIGHTNESS_INC          &kp BACKSPACE    &kp LG(F)         &trans      &kp RIGHT_BRACE        &kp PAGE_DOWN          &kp PAGE_UP
&kp A        &kp G          &Noteful_color_1  &kp LG(N0)      &kp LEFT_BRACE    &kp C_BRIGHTNESS_DEC          &kp RIGHT_BRACE  &kp K_PLAY_PAUSE  &kp C_NEXT  &kp LEFT_BRACE         &Noteful_color_2       &Noteful_color_1
&kp LG(Z)    &kp LG(LS(Z))  &Noteful_color_2  &kp K_PREV      &kp K_PLAY_PAUSE  &kp K_NEXT            &trans  &kp LG(MINUS)    &kp LG(EQUAL)     &kp E       &Noteful_zoom_fit_100  &Noteful_Lasso_eraser  &Noteful_pen_highlight
&kp LC(TAB)  &kp LG(TAB)    &kp LEFT          &kp RIGHT       &kp P             &kp LC(TAB)           &to 2   &kp LC(TAB)      &trans            &kp LG(F)   &kp LC(TAB)            &kp LG(LS(Z))          &kp LG(Z)
            >;

            sensor-bindings = <&inc_dec_kp LG(EQUAL) LG(MINUS)>;
        };

        Notability {
            bindings = <
&kp LG(NUMBER_1)  &kp LG(NUMBER_4)  &kp LG(LA(NUMBER_1))  &kp LG(LA(NUMBER_4))  &kp LG(LS(F))         &kp LG(LA(P))              &kp BACKSPACE  &kp LC(N0)        &kp LG(MINUS)     &kp LG(C)                &kp LG(X)            &kp LG(V)
&kp LG(NUMBER_2)  &kp LG(N5)        &kp LG(LA(NUMBER_2))  &kp LG(LA(N5))        &kp C_BRI_UP          &kp LG(PLUS)               &kp PAGE_UP    &kp LEFT          &kp RIGHT         &Notability_color_swtch  &Notabiltiy_color_1  &Notability_color_2
&kp LG(NUMBER_3)  &kp LG(NUMBER_6)  &kp LA(LG(NUMBER_3))  &kp LG(LA(NUMBER_6))  &kp C_BRIGHTNESS_DEC  &kp LG(MINUS)  &kp LG(N0)  &kp LG(LA(N))  &kp LG(NUMBER_5)  &kp LG(NUMBER_4)  &Notability_size         &Notability_tool_2   &Notability_Tool_1
&kp LG(Z)         &kp LG(LS(Z))     &kp LEFT_ARROW        &kp RIGHT             &kp LC(TAB)           &kp LG(TAB)    &to 2       &kp LG(TAB)    &kp LG(TAB)       &kp LG(F)         &kp LG(LS(P))            &kp LG(LS(Z))        &kp LG(Z)
            >;

            sensor-bindings = <&inc_dec_kp LG(EQUAL) LG(MINUS)>;
        };

        MarginNote {
            bindings = <
&kp LC(N9)        &kp LC(NUMBER_1)  &kp LC(NUMBER_2)  &kp LC(NUMBER_3)  &kp LC(NUMBER_4)  &kp LG(BACKSPACE)          &kp LA(NUMBER_0)  &kp LA(P)      &trans                &trans                &trans                &MN_View_Vertical_Horizontal
&kp LA(NUMBER_1)  &kp LA(NUMBER_2)  &kp LA(LG(I))     &kp LG(D)         &kp LG(LC(S))     &kp LG(LC(K))              &kp LA(LC(R))     &kp LC(LA(Y))  &kp LC(LA(NUMBER_4))  &kp LC(LA(NUMBER_3))  &kp LC(LA(NUMBER_2))  &kp LA(LC(NUMBER_1))
&kp LA(N5)        &kp LS(E)         &kp LG(N0)        &kp LG(G)         &kp LC(LG(R))     &kp LS(M)          &trans  &kp LC(N9)        &kp LC(N0)     &kp LC(NUMBER_4)      &kp LC(NUMBER_3)      &kp LC(NUMBER_2)      &kp LC(NUMBER_1)
&kp LEFT          &kp RIGHT         &kp LG(Z)         &kp LG(LS(Z))     &kp LS(D)         &kp LG(TAB)        &to 2   &kp LC(TAB)       &kp LG(LS(R))  &kp LG(LS(G))         &kp LG(D)             &kp LEFT              &kp RIGHT
            >;

            sensor-bindings = <&inc_dec_kp LG(EQUAL) LG(MINUS)>;
        };
    };
};
